AUTOSAR XML (schema 00046)
package /VehicleProject
  system System
    system mapping System_MPPNG
      data-mappings:
        data-element=VcuRxMsg1_Sig0.VcuRxMsg1_Sig0, system-signal=VcuRxMsg1_Sig0
        data-element=VcuRxMsg1_Sig2.VcuRxMsg1_Sig2, system-signal=VcuRxMsg1_Sig2
        data-element=VcuRxMsg1_Sig1.VcuRxMsg1_Sig1, system-signal=VcuRxMsg1_Sig1
        data-element=VcuRxMsg2_Sig3.VcuRxMsg2_Sig3, system-signal=VcuRxMsg2_Sig3
        data-element=VcuRxMsg1_Sig3.VcuRxMsg1_Sig3, system-signal=VcuRxMsg1_Sig3
        data-element=VcuRxMsg2_Sig0.VcuRxMsg2_Sig0, system-signal=VcuRxMsg2_Sig0
        data-element=VcuRxMsg2_Sig2.VcuRxMsg2_Sig2, system-signal=VcuRxMsg2_Sig2
        data-element=VcuRxMsg2_Sig1.VcuRxMsg2_Sig1, system-signal=VcuRxMsg2_Sig1
        data-element=VcuTxMsg1_Sig1.VcuTxMsg1_Sig1, system-signal=VcuTxMsg1_Sig1
        data-element=VcuTxMsg2_Sig1.VcuTxMsg2_Sig1, system-signal=VcuTxMsg2_Sig1
        data-element=VcuTxMsg2_Sig2.VcuTxMsg2_Sig2, system-signal=VcuTxMsg2_Sig2
        data-element=VcuTxMsg1_Sig3.VcuTxMsg1_Sig3, system-signal=VcuTxMsg1_Sig3
        data-element=VcuTxMsg2_Sig0.VcuTxMsg2_Sig0, system-signal=VcuTxMsg2_Sig0
        data-element=VcuTxMsg2_Sig3.VcuTxMsg2_Sig3, system-signal=VcuTxMsg2_Sig3
        data-element=VcuTxMsg1_Sig2.VcuTxMsg1_Sig2, system-signal=VcuTxMsg1_Sig2
        data-element=VcuTxMsg1_Sig0.VcuTxMsg1_Sig0, system-signal=VcuTxMsg1_Sig0
        data-element=EXT1_Valid.EXT1_Valid, system-signal=EXT1_Valid
        data-element=EXT3_Valid.EXT3_Valid, system-signal=EXT3_Valid
        data-element=EXT_A_IN4.EXT_A_IN4, system-signal=EXT_A_IN4
        data-element=EXT2_Valid.EXT2_Valid, system-signal=EXT2_Valid
        data-element=EXT4_Valid.EXT4_Valid, system-signal=EXT4_Valid
        data-element=EXT_A_IN{1..3}.EXT_A_IN{1..3}, system-signal=EXT_A_IN{1..3}
        data-element=EXT10_Valid.EXT10_Valid, system-signal=EXT10_Valid
        data-element=EXT12_Valid.EXT12_Valid, system-signal=EXT12_Valid
        data-element=EXT15_Valid.EXT15_Valid, system-signal=EXT15_Valid
        data-element=EXT5_Valid.EXT5_Valid, system-signal=EXT5_Valid
        data-element=EXT_A_IN15.EXT_A_IN15, system-signal=EXT_A_IN15
        data-element=EXT7_Valid.EXT7_Valid, system-signal=EXT7_Valid
        data-element=EXT_A_IN13.EXT_A_IN13, system-signal=EXT_A_IN13
        data-element=EXT_A_IN5.EXT_A_IN5, system-signal=EXT_A_IN5
        data-element=EXT6_Valid.EXT6_Valid, system-signal=EXT6_Valid
        data-element=EXT_A_IN12.EXT_A_IN12, system-signal=EXT_A_IN12
        data-element=EXT_A_IN7.EXT_A_IN7, system-signal=EXT_A_IN7
        data-element=EXT13_Valid.EXT13_Valid, system-signal=EXT13_Valid
        data-element=EXT_A_IN9.EXT_A_IN9, system-signal=EXT_A_IN9
        data-element=EXT9_Valid.EXT9_Valid, system-signal=EXT9_Valid
        data-element=EXT8_Valid.EXT8_Valid, system-signal=EXT8_Valid
        data-element=EXT11_Valid.EXT11_Valid, system-signal=EXT11_Valid
        data-element=EXT_A_IN6.EXT_A_IN6, system-signal=EXT_A_IN6
        data-element=EXT16_Valid.EXT16_Valid, system-signal=EXT16_Valid
        data-element=EXT14_Valid.EXT14_Valid, system-signal=EXT14_Valid
        data-element=EXT_A_IN16.EXT_A_IN16, system-signal=EXT_A_IN16
        data-element=EXT_A_IN11.EXT_A_IN11, system-signal=EXT_A_IN11
        data-element=EXT_A_IN8.EXT_A_IN8, system-signal=EXT_A_IN8
        data-element=EXT_A_IN14.EXT_A_IN14, system-signal=EXT_A_IN14
        data-element=EXT_A_IN10.EXT_A_IN10, system-signal=EXT_A_IN10
        data-element=ECC_PMP2_SpdSet.ECC_PMP2_SpdSet, system-signal=ECC_PMP2_SpdSet
        data-element=ECC_PMP3_SpdSet.ECC_PMP3_SpdSet, system-signal=ECC_PMP3_SpdSet
        data-element=AN30.AN30, system-signal=AN30
        data-element=AN22.AN22, system-signal=AN22
        data-element=AN27.AN27, system-signal=AN27
        data-element=AN10.AN10, system-signal=AN10
        data-element=AN24.AN24, system-signal=AN24
        data-element=AN13.AN13, system-signal=AN13
        data-element=AN8.AN8, system-signal=AN8
        data-element=AN0.AN0, system-signal=AN0
        data-element=AN26.AN26, system-signal=AN26
        data-element=AN29.AN29, system-signal=AN29
        data-element=AN3.AN3, system-signal=AN3
        data-element=AN19.AN19, system-signal=AN19
        data-element=AN14.AN14, system-signal=AN14
        data-element=AN42.AN42, system-signal=AN42
        data-element=AN25.AN25, system-signal=AN25
        data-element=AN12.AN12, system-signal=AN12
        data-element=AN9.AN9, system-signal=AN9
        data-element=AN31.AN31, system-signal=AN31
        data-element=AN18.AN18, system-signal=AN18
        data-element=AN5.AN5, system-signal=AN5
        data-element=AN20.AN20, system-signal=AN20
        data-element=AN43.AN43, system-signal=AN43
        data-element=AN15.AN15, system-signal=AN15
        data-element=AN46.AN46, system-signal=AN46
        data-element=AN32.AN32, system-signal=AN32
        data-element=AN34.AN34, system-signal=AN34
        data-element=AN36.AN36, system-signal=AN36
        data-element=AN41.AN41, system-signal=AN41
        data-element=AN44.AN44, system-signal=AN44
        data-element=AN6.AN6, system-signal=AN6
        data-element=AN2.AN2, system-signal=AN2
        data-element=AN7.AN7, system-signal=AN7
        data-element=AN11.AN11, system-signal=AN11
        data-element=AN40.AN40, system-signal=AN40
        data-element=AN47.AN47, system-signal=AN47
        data-element=AN1.AN1, system-signal=AN1
        data-element=AN28.AN28, system-signal=AN28
        data-element=AN37.AN37, system-signal=AN37
        data-element=AN21.AN21, system-signal=AN21
        data-element=AN33.AN33, system-signal=AN33
        data-element=AN23.AN23, system-signal=AN23
        data-element=AN4.AN4, system-signal=AN4
        data-element=AN16.AN16, system-signal=AN16
        data-element=AN17.AN17, system-signal=AN17
        data-element=AN35.AN35, system-signal=AN35
        data-element=AN45.AN45, system-signal=AN45
        data-element=AN38.AN38, system-signal=AN38
        data-element=AN39.AN39, system-signal=AN39
        data-element=Tle888qk_Out23_En.Tle888qk_Out23_En, system-signal=Tle888qk_Out23_En
        data-element=Tle888qk_Out22_En.Tle888qk_Out22_En, system-signal=Tle888qk_Out22_En
        data-element=Tle888qk_Out21_En.Tle888qk_Out21_En, system-signal=Tle888qk_Out21_En
        data-element=Bts7xx_HS3_En.Bts7xx_HS3_En, system-signal=Bts7xx_HS3_En
        data-element=Bts7xx_HS1_En.Bts7xx_HS1_En, system-signal=Bts7xx_HS1_En
        data-element=Bts7xx_HS4_En.Bts7xx_HS4_En, system-signal=Bts7xx_HS4_En
        data-element=Bts7xx_HS2_En.Bts7xx_HS2_En, system-signal=Bts7xx_HS2_En
        data-element=Tle888qk_Out24_En.Tle888qk_Out24_En, system-signal=Tle888qk_Out24_En
        data-element=Tle9201_Dir.Tle9201_Dir, system-signal=Tle9201_Dir
        data-element=Tle9201_Pwm.Tle9201_Pwm, system-signal=Tle9201_Pwm
        data-element=Tle9201_Dis.Tle9201_Dis, system-signal=Tle9201_Dis
        data-element=Tle4252d_en.Tle4252d_en, system-signal=Tle4252d_en
        data-element=Tle888qk_Out22BriCfg.Tle888qk_Out22BriCfg, system-signal=Tle888qk_Out22BriCfg
        data-element=Tle888qk_Out23BriCfg.Tle888qk_Out23BriCfg, system-signal=Tle888qk_Out23BriCfg
        data-element=Tle888qk_Out21BriCfg.Tle888qk_Out21BriCfg, system-signal=Tle888qk_Out21BriCfg
        data-element=Tle888qk_Out24BriCfg.Tle888qk_Out24BriCfg, system-signal=Tle888qk_Out24BriCfg
        data-element=Ext_IN2.Ext_IN2, system-signal=Ext_IN2
        data-element=EXT_PWM_IN1_Duty.EXT_PWM_IN1_Duty, system-signal=EXT_PWM_IN1_Duty
        data-element=EXT_PWM_IN2_Duty.EXT_PWM_IN2_Duty, system-signal=EXT_PWM_IN2_Duty
        data-element=EXT_PWM_IN2_Period.EXT_PWM_IN2_Period, system-signal=EXT_PWM_IN2_Period
        data-element=EXT_PWM_IN1_Period.EXT_PWM_IN1_Period, system-signal=EXT_PWM_IN1_Period
        data-element=Tle888qk_Lout1_En.Tle888qk_Lout1_En, system-signal=Tle888qk_Lout1_En
        data-element=Tle888qk_Lout8_En.Tle888qk_Lout8_En, system-signal=Tle888qk_Lout8_En
        data-element=Tle888qk_Lout14_En.Tle888qk_Lout14_En, system-signal=Tle888qk_Lout14_En
        data-element=Tle888qk_Lout16_En.Tle888qk_Lout16_En, system-signal=Tle888qk_Lout16_En
    root-software-compositions:
      root sw composition prototype EcuSwComposition: software-composition=ECU_Composition
package /ECUCompositionTypes
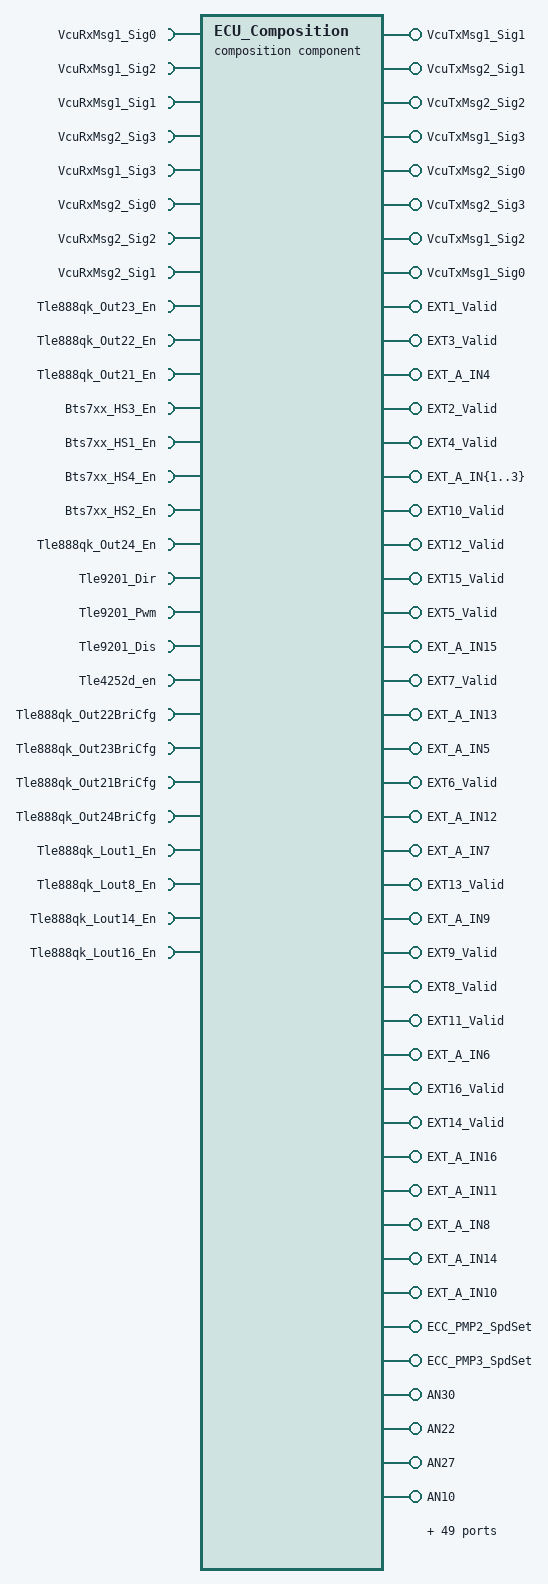
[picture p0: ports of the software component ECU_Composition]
  composition sw component type ECU_Composition
    8 x require port:
      VcuRxMsg1_Sig0: nonqueued-receiver-com-spec{data-element=VcuRxMsg1_Sig0, init-value=0}, required-interface=VcuRxMsg1_Sig0
      VcuRxMsg1_Sig2: nonqueued-receiver-com-spec{data-element=VcuRxMsg1_Sig2, init-value=0}, required-interface=VcuRxMsg1_Sig2
      VcuRxMsg1_Sig1: nonqueued-receiver-com-spec{data-element=VcuRxMsg1_Sig1, init-value=0}, required-interface=VcuRxMsg1_Sig1
      VcuRxMsg2_Sig3: nonqueued-receiver-com-spec{data-element=VcuRxMsg2_Sig3, init-value=0}, required-interface=VcuRxMsg2_Sig3
      VcuRxMsg1_Sig3: nonqueued-receiver-com-spec{data-element=VcuRxMsg1_Sig3, init-value=0}, required-interface=VcuRxMsg1_Sig3
      VcuRxMsg2_Sig0: nonqueued-receiver-com-spec{data-element=VcuRxMsg2_Sig0, init-value=0}, required-interface=VcuRxMsg2_Sig0
      VcuRxMsg2_Sig2: nonqueued-receiver-com-spec{data-element=VcuRxMsg2_Sig2, init-value=0}, required-interface=VcuRxMsg2_Sig2
      VcuRxMsg2_Sig1: nonqueued-receiver-com-spec{data-element=VcuRxMsg2_Sig1, init-value=0}, required-interface=VcuRxMsg2_Sig1
    90 x provide port:
      VcuTxMsg1_Sig1: nonqueued-sender-com-spec{data-element=VcuTxMsg1_Sig1, init-value=0}, provided-interface=VcuTxMsg1_Sig1
      VcuTxMsg2_Sig1: nonqueued-sender-com-spec{data-element=VcuTxMsg2_Sig1, init-value=0}, provided-interface=VcuTxMsg2_Sig1
      VcuTxMsg2_Sig2: nonqueued-sender-com-spec{data-element=VcuTxMsg2_Sig2, init-value=0}, provided-interface=VcuTxMsg2_Sig2
      VcuTxMsg1_Sig3: nonqueued-sender-com-spec{data-element=VcuTxMsg1_Sig3, init-value=0}, provided-interface=VcuTxMsg1_Sig3
      VcuTxMsg2_Sig0: nonqueued-sender-com-spec{data-element=VcuTxMsg2_Sig0, init-value=0}, provided-interface=VcuTxMsg2_Sig0
      VcuTxMsg2_Sig3: nonqueued-sender-com-spec{data-element=VcuTxMsg2_Sig3, init-value=0}, provided-interface=VcuTxMsg2_Sig3
      VcuTxMsg1_Sig2: nonqueued-sender-com-spec{data-element=VcuTxMsg1_Sig2, init-value=0}, provided-interface=VcuTxMsg1_Sig2
      VcuTxMsg1_Sig0: nonqueued-sender-com-spec{data-element=VcuTxMsg1_Sig0, init-value=0}, provided-interface=VcuTxMsg1_Sig0
      EXT1_Valid: nonqueued-sender-com-spec{data-element=EXT1_Valid, init-value=0}, provided-interface=EXT1_Valid
      EXT3_Valid: nonqueued-sender-com-spec{data-element=EXT3_Valid, init-value=0}, provided-interface=EXT3_Valid
      EXT_A_IN4: nonqueued-sender-com-spec{data-element=EXT_A_IN4, init-value=0}, provided-interface=EXT_A_IN4
      EXT2_Valid: nonqueued-sender-com-spec{data-element=EXT2_Valid, init-value=0}, provided-interface=EXT2_Valid
      EXT4_Valid: nonqueued-sender-com-spec{data-element=EXT4_Valid, init-value=0}, provided-interface=EXT4_Valid
      EXT_A_IN{1..3}: nonqueued-sender-com-spec{data-element=EXT_A_IN{1..3}, init-value=0}, provided-interface=EXT_A_IN{1..3}
      EXT10_Valid: nonqueued-sender-com-spec{data-element=EXT10_Valid, init-value=0}, provided-interface=EXT10_Valid
      EXT12_Valid: nonqueued-sender-com-spec{data-element=EXT12_Valid, init-value=0}, provided-interface=EXT12_Valid
      EXT15_Valid: nonqueued-sender-com-spec{data-element=EXT15_Valid, init-value=0}, provided-interface=EXT15_Valid
      EXT5_Valid: nonqueued-sender-com-spec{data-element=EXT5_Valid, init-value=0}, provided-interface=EXT5_Valid
      EXT_A_IN15: nonqueued-sender-com-spec{data-element=EXT_A_IN15, init-value=0}, provided-interface=EXT_A_IN15
      EXT7_Valid: nonqueued-sender-com-spec{data-element=EXT7_Valid, init-value=0}, provided-interface=EXT7_Valid
      EXT_A_IN13: nonqueued-sender-com-spec{data-element=EXT_A_IN13, init-value=0}, provided-interface=EXT_A_IN13
      EXT_A_IN5: nonqueued-sender-com-spec{data-element=EXT_A_IN5, init-value=0}, provided-interface=EXT_A_IN5
      EXT6_Valid: nonqueued-sender-com-spec{data-element=EXT6_Valid, init-value=0}, provided-interface=EXT6_Valid
      EXT_A_IN12: nonqueued-sender-com-spec{data-element=EXT_A_IN12, init-value=0}, provided-interface=EXT_A_IN12
      EXT_A_IN7: nonqueued-sender-com-spec{data-element=EXT_A_IN7, init-value=0}, provided-interface=EXT_A_IN7
      EXT13_Valid: nonqueued-sender-com-spec{data-element=EXT13_Valid, init-value=0}, provided-interface=EXT13_Valid
      EXT_A_IN9: nonqueued-sender-com-spec{data-element=EXT_A_IN9, init-value=0}, provided-interface=EXT_A_IN9
      EXT9_Valid: nonqueued-sender-com-spec{data-element=EXT9_Valid, init-value=0}, provided-interface=EXT9_Valid
      EXT8_Valid: nonqueued-sender-com-spec{data-element=EXT8_Valid, init-value=0}, provided-interface=EXT8_Valid
      EXT11_Valid: nonqueued-sender-com-spec{data-element=EXT11_Valid, init-value=0}, provided-interface=EXT11_Valid
      EXT_A_IN6: nonqueued-sender-com-spec{data-element=EXT_A_IN6, init-value=0}, provided-interface=EXT_A_IN6
      EXT16_Valid: nonqueued-sender-com-spec{data-element=EXT16_Valid, init-value=0}, provided-interface=EXT16_Valid
      EXT14_Valid: nonqueued-sender-com-spec{data-element=EXT14_Valid, init-value=0}, provided-interface=EXT14_Valid
      EXT_A_IN16: nonqueued-sender-com-spec{data-element=EXT_A_IN16, init-value=0}, provided-interface=EXT_A_IN16
      EXT_A_IN11: nonqueued-sender-com-spec{data-element=EXT_A_IN11, init-value=0}, provided-interface=EXT_A_IN11
      EXT_A_IN8: nonqueued-sender-com-spec{data-element=EXT_A_IN8, init-value=0}, provided-interface=EXT_A_IN8
      EXT_A_IN14: nonqueued-sender-com-spec{data-element=EXT_A_IN14, init-value=0}, provided-interface=EXT_A_IN14
      EXT_A_IN10: nonqueued-sender-com-spec{data-element=EXT_A_IN10, init-value=0}, provided-interface=EXT_A_IN10
      ECC_PMP2_SpdSet: nonqueued-sender-com-spec{data-element=ECC_PMP2_SpdSet, init-value=0}, provided-interface=ECC_PMP2_SpdSet
      ECC_PMP3_SpdSet: nonqueued-sender-com-spec{data-element=ECC_PMP3_SpdSet, init-value=0}, provided-interface=ECC_PMP3_SpdSet
      AN30: nonqueued-sender-com-spec{data-element=AN30, init-value=0}, provided-interface=AN30
      AN22: nonqueued-sender-com-spec{data-element=AN22, init-value=0}, provided-interface=AN22
      AN27: nonqueued-sender-com-spec{data-element=AN27, init-value=0}, provided-interface=AN27
      AN10: nonqueued-sender-com-spec{data-element=AN10, init-value=0}, provided-interface=AN10
      AN24: nonqueued-sender-com-spec{data-element=AN24, init-value=0}, provided-interface=AN24
      AN13: nonqueued-sender-com-spec{data-element=AN13, init-value=0}, provided-interface=AN13
      AN8: nonqueued-sender-com-spec{data-element=AN8, init-value=0}, provided-interface=AN8
      AN0: nonqueued-sender-com-spec{data-element=AN0, init-value=0}, provided-interface=AN0
      AN26: nonqueued-sender-com-spec{data-element=AN26, init-value=0}, provided-interface=AN26
      AN29: nonqueued-sender-com-spec{data-element=AN29, init-value=0}, provided-interface=AN29
      AN3: nonqueued-sender-com-spec{data-element=AN3, init-value=0}, provided-interface=AN3
      AN19: nonqueued-sender-com-spec{data-element=AN19, init-value=0}, provided-interface=AN19
      AN14: nonqueued-sender-com-spec{data-element=AN14, init-value=0}, provided-interface=AN14
      AN42: nonqueued-sender-com-spec{data-element=AN42, init-value=0}, provided-interface=AN42
      AN25: nonqueued-sender-com-spec{data-element=AN25, init-value=0}, provided-interface=AN25
      AN12: nonqueued-sender-com-spec{data-element=AN12, init-value=0}, provided-interface=AN12
      AN9: nonqueued-sender-com-spec{data-element=AN9, init-value=0}, provided-interface=AN9
      AN31: nonqueued-sender-com-spec{data-element=AN31, init-value=0}, provided-interface=AN31
      AN18: nonqueued-sender-com-spec{data-element=AN18, init-value=0}, provided-interface=AN18
      AN5: nonqueued-sender-com-spec{data-element=AN5, init-value=0}, provided-interface=AN5
      AN20: nonqueued-sender-com-spec{data-element=AN20, init-value=0}, provided-interface=AN20
      AN43: nonqueued-sender-com-spec{data-element=AN43, init-value=0}, provided-interface=AN43
      AN15: nonqueued-sender-com-spec{data-element=AN15, init-value=0}, provided-interface=AN15
      AN46: nonqueued-sender-com-spec{data-element=AN46, init-value=0}, provided-interface=AN46
      AN32: nonqueued-sender-com-spec{data-element=AN32, init-value=0}, provided-interface=AN32
      AN34: nonqueued-sender-com-spec{data-element=AN34, init-value=0}, provided-interface=AN34
      AN36: nonqueued-sender-com-spec{data-element=AN36, init-value=0}, provided-interface=AN36
      AN41: nonqueued-sender-com-spec{data-element=AN41, init-value=0}, provided-interface=AN41
      AN44: nonqueued-sender-com-spec{data-element=AN44, init-value=0}, provided-interface=AN44
      AN6: nonqueued-sender-com-spec{data-element=AN6, init-value=0}, provided-interface=AN6
      AN2: nonqueued-sender-com-spec{data-element=AN2, init-value=0}, provided-interface=AN2
      AN7: nonqueued-sender-com-spec{data-element=AN7, init-value=0}, provided-interface=AN7
      AN11: nonqueued-sender-com-spec{data-element=AN11, init-value=0}, provided-interface=AN11
      AN40: nonqueued-sender-com-spec{data-element=AN40, init-value=0}, provided-interface=AN40
      AN47: nonqueued-sender-com-spec{data-element=AN47, init-value=0}, provided-interface=AN47
      AN1: nonqueued-sender-com-spec{data-element=AN1, init-value=0}, provided-interface=AN1
      AN28: nonqueued-sender-com-spec{data-element=AN28, init-value=0}, provided-interface=AN28
      AN37: nonqueued-sender-com-spec{data-element=AN37, init-value=0}, provided-interface=AN37
      AN21: nonqueued-sender-com-spec{data-element=AN21, init-value=0}, provided-interface=AN21
      AN33: nonqueued-sender-com-spec{data-element=AN33, init-value=0}, provided-interface=AN33
      AN23: nonqueued-sender-com-spec{data-element=AN23, init-value=0}, provided-interface=AN23
      AN4: nonqueued-sender-com-spec{data-element=AN4, init-value=0}, provided-interface=AN4
      AN16: nonqueued-sender-com-spec{data-element=AN16, init-value=0}, provided-interface=AN16
      AN17: nonqueued-sender-com-spec{data-element=AN17, init-value=0}, provided-interface=AN17
      AN35: nonqueued-sender-com-spec{data-element=AN35, init-value=0}, provided-interface=AN35
      AN45: nonqueued-sender-com-spec{data-element=AN45, init-value=0}, provided-interface=AN45
      AN38: nonqueued-sender-com-spec{data-element=AN38, init-value=0}, provided-interface=AN38
      AN39: nonqueued-sender-com-spec{data-element=AN39, init-value=0}, provided-interface=AN39
    16 x require port:
      Tle888qk_Out23_En: nonqueued-receiver-com-spec{data-element=Tle888qk_Out23_En, init-value=0}, required-interface=Tle888qk_Out23_En
      Tle888qk_Out22_En: nonqueued-receiver-com-spec{data-element=Tle888qk_Out22_En, init-value=0}, required-interface=Tle888qk_Out22_En
      Tle888qk_Out21_En: nonqueued-receiver-com-spec{data-element=Tle888qk_Out21_En, init-value=0}, required-interface=Tle888qk_Out21_En
      Bts7xx_HS3_En: nonqueued-receiver-com-spec{data-element=Bts7xx_HS3_En, init-value=0}, required-interface=Bts7xx_HS3_En
      Bts7xx_HS1_En: nonqueued-receiver-com-spec{data-element=Bts7xx_HS1_En, init-value=0}, required-interface=Bts7xx_HS1_En
      Bts7xx_HS4_En: nonqueued-receiver-com-spec{data-element=Bts7xx_HS4_En, init-value=0}, required-interface=Bts7xx_HS4_En
      Bts7xx_HS2_En: nonqueued-receiver-com-spec{data-element=Bts7xx_HS2_En, init-value=0}, required-interface=Bts7xx_HS2_En
      Tle888qk_Out24_En: nonqueued-receiver-com-spec{data-element=Tle888qk_Out24_En, init-value=0}, required-interface=Tle888qk_Out24_En
      Tle9201_Dir: nonqueued-receiver-com-spec{data-element=Tle9201_Dir, init-value=0}, required-interface=Tle9201_Dir
      Tle9201_Pwm: nonqueued-receiver-com-spec{data-element=Tle9201_Pwm, init-value=0}, required-interface=Tle9201_Pwm
      Tle9201_Dis: nonqueued-receiver-com-spec{data-element=Tle9201_Dis, init-value=0}, required-interface=Tle9201_Dis
      Tle4252d_en: nonqueued-receiver-com-spec{data-element=Tle4252d_en, init-value=0}, required-interface=Tle4252d_en
      Tle888qk_Out22BriCfg: nonqueued-receiver-com-spec{data-element=Tle888qk_Out22BriCfg, init-value=0}, required-interface=Tle888qk_Out22BriCfg
      Tle888qk_Out23BriCfg: nonqueued-receiver-com-spec{data-element=Tle888qk_Out23BriCfg, init-value=0}, required-interface=Tle888qk_Out23BriCfg
      Tle888qk_Out21BriCfg: nonqueued-receiver-com-spec{data-element=Tle888qk_Out21BriCfg, init-value=0}, required-interface=Tle888qk_Out21BriCfg
      Tle888qk_Out24BriCfg: nonqueued-receiver-com-spec{data-element=Tle888qk_Out24BriCfg, init-value=0}, required-interface=Tle888qk_Out24BriCfg
    5 x provide port:
      Ext_IN2: nonqueued-sender-com-spec{data-element=Ext_IN2, init-value=0}, provided-interface=Ext_IN2
      EXT_PWM_IN1_Duty: nonqueued-sender-com-spec{data-element=EXT_PWM_IN1_Duty, init-value=0}, provided-interface=EXT_PWM_IN1_Duty
      EXT_PWM_IN2_Duty: nonqueued-sender-com-spec{data-element=EXT_PWM_IN2_Duty, init-value=0}, provided-interface=EXT_PWM_IN2_Duty
      EXT_PWM_IN2_Period: nonqueued-sender-com-spec{data-element=EXT_PWM_IN2_Period, init-value=0}, provided-interface=EXT_PWM_IN2_Period
      EXT_PWM_IN1_Period: nonqueued-sender-com-spec{data-element=EXT_PWM_IN1_Period, init-value=0}, provided-interface=EXT_PWM_IN1_Period
    4 x require port:
      Tle888qk_Lout1_En: nonqueued-receiver-com-spec{data-element=Tle888qk_Lout1_En, init-value=0}, required-interface=Tle888qk_Lout1_En
      Tle888qk_Lout8_En: nonqueued-receiver-com-spec{data-element=Tle888qk_Lout8_En, init-value=0}, required-interface=Tle888qk_Lout8_En
      Tle888qk_Lout14_En: nonqueued-receiver-com-spec{data-element=Tle888qk_Lout14_En, init-value=0}, required-interface=Tle888qk_Lout14_En
      Tle888qk_Lout16_En: nonqueued-receiver-com-spec{data-element=Tle888qk_Lout16_En, init-value=0}, required-interface=Tle888qk_Lout16_En
    7 x component:
      SWC1: type=SWC1
      PowerMng_SWC: type=PowerMng_SWC
      Com_SWC: type=Com_SWC
      NvM_SWC: type=NvM_SWC
      DIAG_SWC: type=DIAG_SWC
      IoHwAb_SWC: type=IoHwAb_SWC
      IoHwAb: type=IoHwAb
    delegate Com_SWC.VcuRxMsg1_Sig0 <-> outer port VcuRxMsg1_Sig0
    delegate Com_SWC.VcuRxMsg1_Sig2 <-> outer port VcuRxMsg1_Sig2
    delegate Com_SWC.VcuRxMsg1_Sig1 <-> outer port VcuRxMsg1_Sig1
    delegate Com_SWC.VcuRxMsg2_Sig3 <-> outer port VcuRxMsg2_Sig3
    delegate Com_SWC.VcuRxMsg1_Sig3 <-> outer port VcuRxMsg1_Sig3
    delegate Com_SWC.VcuRxMsg2_Sig0 <-> outer port VcuRxMsg2_Sig0
    delegate Com_SWC.VcuRxMsg2_Sig2 <-> outer port VcuRxMsg2_Sig2
    delegate Com_SWC.VcuRxMsg2_Sig1 <-> outer port VcuRxMsg2_Sig1
    delegate Com_SWC.VcuTxMsg1_Sig1 <-> outer port VcuTxMsg1_Sig1
    delegate Com_SWC.VcuTxMsg2_Sig1 <-> outer port VcuTxMsg2_Sig1
    delegate Com_SWC.VcuTxMsg2_Sig2 <-> outer port VcuTxMsg2_Sig2
    delegate Com_SWC.VcuTxMsg1_Sig3 <-> outer port VcuTxMsg1_Sig3
    delegate Com_SWC.VcuTxMsg2_Sig0 <-> outer port VcuTxMsg2_Sig0
    delegate Com_SWC.VcuTxMsg2_Sig3 <-> outer port VcuTxMsg2_Sig3
    delegate Com_SWC.VcuTxMsg1_Sig2 <-> outer port VcuTxMsg1_Sig2
    delegate Com_SWC.VcuTxMsg1_Sig0 <-> outer port VcuTxMsg1_Sig0
    connect NvM_SWC.NvM_Data_IF_UserData1_Send -> SWC1.NvM_Data_IF_UserData1_Recv
    connect SWC1.NvSWC_NvMNotifyJobFinished_UserData1 -> NvM_SWC.NvSWC_NvMNotifyJobFinished_NVBlockDescriptor_UserData1
    connect SWC1.NvM_Data_IF_UserData1_Send -> NvM_SWC.NvM_Data_IF_UserData1_Recv
    connect SWC1.NvM_Data_IF_UserData2_Send -> NvM_SWC.NvM_Data_IF_UserData2_Rcev
    connect NvM_SWC.NvM_Data_IF_UserData2_Send -> SWC1.NvM_Data_IF_UserData2_Recv
    connect SWC1.NvSWC_NvMNotifyJobFinished_UserData2 -> NvM_SWC.NvSWC_NvMNotifyJobFinished_NVBlockDescriptor_UserData2
    connect NvM_SWC.NvMService_NVBlockDescriptor_UserData2 -> SWC1.NvSWC_UserData2_NvMService_AC3_SRBS
    delegate Com_SWC.EXT1_Valid <-> outer port EXT1_Valid
    delegate Com_SWC.EXT3_Valid <-> outer port EXT3_Valid
    delegate Com_SWC.EXT_A_IN4 <-> outer port EXT_A_IN4
    delegate Com_SWC.EXT2_Valid <-> outer port EXT2_Valid
    delegate Com_SWC.EXT4_Valid <-> outer port EXT4_Valid
    delegate Com_SWC.EXT_A_IN{1..3} <-> outer port EXT_A_IN{1..3}
    delegate Com_SWC.EXT10_Valid <-> outer port EXT10_Valid
    delegate Com_SWC.EXT12_Valid <-> outer port EXT12_Valid
    delegate Com_SWC.EXT15_Valid <-> outer port EXT15_Valid
    delegate Com_SWC.EXT5_Valid <-> outer port EXT5_Valid
    delegate Com_SWC.EXT_A_IN15 <-> outer port EXT_A_IN15
    delegate Com_SWC.EXT7_Valid <-> outer port EXT7_Valid
    delegate Com_SWC.EXT_A_IN13 <-> outer port EXT_A_IN13
    delegate Com_SWC.EXT_A_IN5 <-> outer port EXT_A_IN5
    delegate Com_SWC.EXT6_Valid <-> outer port EXT6_Valid
    delegate Com_SWC.EXT_A_IN12 <-> outer port EXT_A_IN12
    delegate Com_SWC.EXT_A_IN7 <-> outer port EXT_A_IN7
    delegate Com_SWC.EXT13_Valid <-> outer port EXT13_Valid
    delegate Com_SWC.EXT_A_IN9 <-> outer port EXT_A_IN9
    delegate Com_SWC.EXT9_Valid <-> outer port EXT9_Valid
    delegate Com_SWC.EXT8_Valid <-> outer port EXT8_Valid
    delegate Com_SWC.EXT11_Valid <-> outer port EXT11_Valid
    delegate Com_SWC.EXT_A_IN6 <-> outer port EXT_A_IN6
    delegate Com_SWC.EXT16_Valid <-> outer port EXT16_Valid
    delegate Com_SWC.EXT14_Valid <-> outer port EXT14_Valid
    delegate Com_SWC.EXT_A_IN16 <-> outer port EXT_A_IN16
    delegate Com_SWC.EXT_A_IN11 <-> outer port EXT_A_IN11
    delegate Com_SWC.EXT_A_IN8 <-> outer port EXT_A_IN8
    delegate Com_SWC.EXT_A_IN14 <-> outer port EXT_A_IN14
    delegate Com_SWC.EXT_A_IN10 <-> outer port EXT_A_IN10
    delegate Com_SWC.ECC_PMP2_SpdSet <-> outer port ECC_PMP2_SpdSet
    delegate Com_SWC.ECC_PMP3_SpdSet <-> outer port ECC_PMP3_SpdSet
    delegate Com_SWC.AN30 <-> outer port AN30
    delegate Com_SWC.AN22 <-> outer port AN22
    delegate Com_SWC.AN27 <-> outer port AN27
    delegate Com_SWC.AN10 <-> outer port AN10
    delegate Com_SWC.AN24 <-> outer port AN24
    delegate Com_SWC.AN13 <-> outer port AN13
    delegate Com_SWC.AN8 <-> outer port AN8
    delegate Com_SWC.AN0 <-> outer port AN0
    delegate Com_SWC.AN26 <-> outer port AN26
    delegate Com_SWC.AN29 <-> outer port AN29
    delegate Com_SWC.AN3 <-> outer port AN3
    delegate Com_SWC.AN19 <-> outer port AN19
    delegate Com_SWC.AN14 <-> outer port AN14
    delegate Com_SWC.AN42 <-> outer port AN42
    delegate Com_SWC.AN25 <-> outer port AN25
    delegate Com_SWC.AN12 <-> outer port AN12
    delegate Com_SWC.AN9 <-> outer port AN9
    delegate Com_SWC.AN31 <-> outer port AN31
    delegate Com_SWC.AN18 <-> outer port AN18
    delegate Com_SWC.AN5 <-> outer port AN5
    delegate Com_SWC.AN20 <-> outer port AN20
    delegate Com_SWC.AN43 <-> outer port AN43
    delegate Com_SWC.AN15 <-> outer port AN15
    delegate Com_SWC.AN46 <-> outer port AN46
    delegate Com_SWC.AN32 <-> outer port AN32
    delegate Com_SWC.AN34 <-> outer port AN34
    delegate Com_SWC.AN36 <-> outer port AN36
    delegate Com_SWC.AN41 <-> outer port AN41
    delegate Com_SWC.AN44 <-> outer port AN44
    delegate Com_SWC.AN6 <-> outer port AN6
    delegate Com_SWC.AN2 <-> outer port AN2
    delegate Com_SWC.AN7 <-> outer port AN7
    delegate Com_SWC.AN11 <-> outer port AN11
    delegate Com_SWC.AN40 <-> outer port AN40
    delegate Com_SWC.AN47 <-> outer port AN47
    delegate Com_SWC.AN1 <-> outer port AN1
    delegate Com_SWC.AN28 <-> outer port AN28
    delegate Com_SWC.AN37 <-> outer port AN37
    delegate Com_SWC.AN21 <-> outer port AN21
    delegate Com_SWC.AN33 <-> outer port AN33
    delegate Com_SWC.AN23 <-> outer port AN23
    delegate Com_SWC.AN4 <-> outer port AN4
    delegate Com_SWC.AN16 <-> outer port AN16
    delegate Com_SWC.AN17 <-> outer port AN17
    delegate Com_SWC.AN35 <-> outer port AN35
    delegate Com_SWC.AN45 <-> outer port AN45
    delegate Com_SWC.AN38 <-> outer port AN38
    delegate Com_SWC.AN39 <-> outer port AN39
    connect IoHwAb.IoHwAbCSPortPrototype -> PowerMng_SWC.IoHwAbCSPortInterface
    delegate Com_SWC.Tle888qk_Out23_En <-> outer port Tle888qk_Out23_En
    delegate Com_SWC.Tle888qk_Out22_En <-> outer port Tle888qk_Out22_En
    delegate Com_SWC.Tle888qk_Out21_En <-> outer port Tle888qk_Out21_En
    delegate Com_SWC.Bts7xx_HS3_En <-> outer port Bts7xx_HS3_En
    delegate Com_SWC.Bts7xx_HS1_En <-> outer port Bts7xx_HS1_En
    delegate Com_SWC.Bts7xx_HS4_En <-> outer port Bts7xx_HS4_En
    delegate Com_SWC.Bts7xx_HS2_En <-> outer port Bts7xx_HS2_En
    delegate Com_SWC.Tle888qk_Out24_En <-> outer port Tle888qk_Out24_En
    delegate Com_SWC.Tle9201_Dir <-> outer port Tle9201_Dir
    delegate Com_SWC.Tle9201_Pwm <-> outer port Tle9201_Pwm
    delegate Com_SWC.Tle9201_Dis <-> outer port Tle9201_Dis
    delegate Com_SWC.Tle4252d_en <-> outer port Tle4252d_en
    delegate Com_SWC.Tle888qk_Out22BriCfg <-> outer port Tle888qk_Out22BriCfg
    delegate Com_SWC.Tle888qk_Out23BriCfg <-> outer port Tle888qk_Out23BriCfg
    delegate Com_SWC.Tle888qk_Out21BriCfg <-> outer port Tle888qk_Out21BriCfg
    delegate Com_SWC.Tle888qk_Out24BriCfg <-> outer port Tle888qk_Out24BriCfg
    delegate Com_SWC.Ext_IN2 <-> outer port Ext_IN2
    delegate Com_SWC.EXT_PWM_IN1_Duty <-> outer port EXT_PWM_IN1_Duty
    delegate Com_SWC.EXT_PWM_IN2_Duty <-> outer port EXT_PWM_IN2_Duty
    delegate Com_SWC.EXT_PWM_IN2_Period <-> outer port EXT_PWM_IN2_Period
    delegate Com_SWC.EXT_PWM_IN1_Period <-> outer port EXT_PWM_IN1_Period
    delegate Com_SWC.Tle888qk_Lout1_En <-> outer port Tle888qk_Lout1_En
    delegate Com_SWC.Tle888qk_Lout8_En <-> outer port Tle888qk_Lout8_En
    delegate Com_SWC.Tle888qk_Lout14_En <-> outer port Tle888qk_Lout14_En
    delegate Com_SWC.Tle888qk_Lout16_En <-> outer port Tle888qk_Lout16_En
package /EndToEndProtections
  end to end protection set EndToEndProtectionSet
